# STM32L4R5 register map
File version: 2.4
CPU: CM4 r0p1, little endian, MPU, FPU, 4 interrupt priority bits
Registers are 32-bit, read-write, reset 0x0 unless marked. A register's access mark holds for its fields unless they carry their own. Offsets are from the block's base; [hi:lo] are bit positions; {n}, {i} and the like mark numbered series; 'fields as' and 'values as' point back to an identical list.

## RCC — Reset and clock control
Base 0x40021000
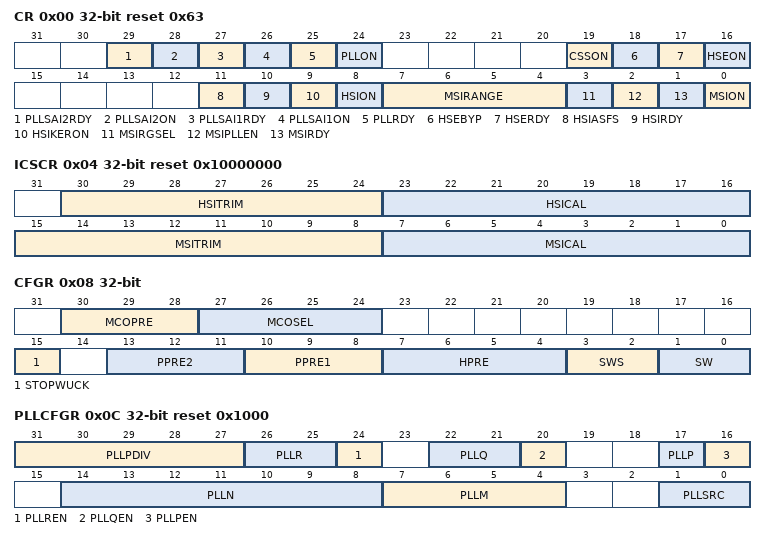
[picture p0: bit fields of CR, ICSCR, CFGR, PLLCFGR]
0x00 CR access per field reset 0x63 — Clock control register
  [29] PLLSAI2RDY ro — SAI2 PLL clock ready flag
  [28] PLLSAI2ON rw — SAI2 PLL enable
  [27] PLLSAI1RDY ro — SAI1 PLL clock ready flag
  [26] PLLSAI1ON rw — SAI1 PLL enable
  [25] PLLRDY ro — Main PLL clock ready flag
  [24] PLLON rw — Main PLL enable
  [19] CSSON wo — Clock security system enable
  [18] HSEBYP rw — HSE crystal oscillator bypass
  [17] HSERDY ro — HSE clock ready flag
  [16] HSEON rw — HSE clock enable
  [11] HSIASFS rw — HSI automatic start from Stop
  [10] HSIRDY ro — HSI clock ready flag
  [9] HSIKERON rw — HSI always enable for peripheral kernels
  [8] HSION rw — HSI clock enable
  [7:4] MSIRANGE rw — MSI clock ranges
    0=Range100K (range 0 around 100 kHz); 1=Range200K (range 1 around 200 kHz); 2=Range400K (range 2 around 400 kHz); 3=Range800K (range 3 around 800 kHz); 4=Range1M (range 4 around 1 MHz); 5=Range2M (range 5 around 2 MHz); 6=Range4M (range 6 around 4 MHz); 7=Range8M (range 7 around 8 MHz); 8=Range16M (range 8 around 16 MHz); 9=Range24M (range 9 around 24 MHz); 10=Range32M (range 10 around 32 MHz); 11=Range48M (range 11 around 48 MHz)
  [3] MSIRGSEL wo — MSI clock range selection
  [2] MSIPLLEN rw — MSI clock PLL enable
  [1] MSIRDY ro — MSI clock ready flag
  [0] MSION rw — MSI clock enable
0x04 ICSCR access per field reset 0x10000000 — Internal clock sources calibration register
  [30:24] HSITRIM rw — HSI clock trimming
  [23:16] HSICAL ro — HSI clock calibration
  [15:8] MSITRIM rw — MSI clock trimming
  [7:0] MSICAL ro — MSI clock calibration
0x08 CFGR access per field — Clock configuration register
  [30:28] MCOPRE ro — Microcontroller clock output prescaler
  [27:24] MCOSEL rw — Microcontroller clock output
  [15] STOPWUCK rw — Wakeup from Stop and CSS backup clock selection
  [13:11] PPRE2 rw — APB high-speed prescaler (APB2)
  [10:8] PPRE1 rw — PB low-speed prescaler (APB1)
  [7:4] HPRE rw — AHB prescaler
  [3:2] SWS ro — System clock switch status
  [1:0] SW rw — System clock switch
0x0C PLLCFGR reset 0x1000 — PLL configuration register
  [31:27] PLLPDIV — Main PLL division factor for PLLSAI2CLK
  [26:25] PLLR — Main PLL division factor for PLLCLK (system clock)
  [24] PLLREN — Main PLL PLLCLK output enable
  [22:21] PLLQ — Main PLL division factor for PLLUSB1CLK(48 MHz clock)
  [20] PLLQEN — Main PLL PLLUSB1CLK output enable
  [17] PLLP — Main PLL division factor for PLLSAI3CLK (SAI1 and SAI2 clock)
  [16] PLLPEN — Main PLL PLLSAI3CLK output enable
  [14:8] PLLN — Main PLL multiplication factor for VCO
  [7:4] PLLM — Division factor for the main PLL and audio PLL (PLLSAI1 and PLLSAI2) input clock
  [1:0] PLLSRC — Main PLL, PLLSAI1 and PLLSAI2 entry clock source
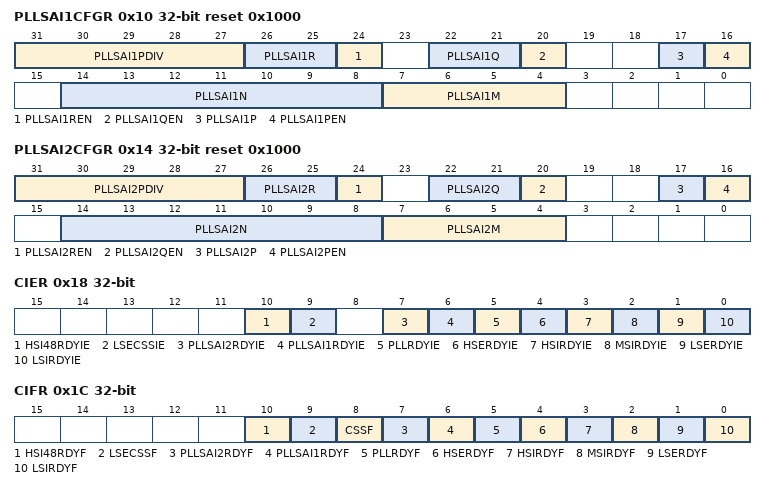
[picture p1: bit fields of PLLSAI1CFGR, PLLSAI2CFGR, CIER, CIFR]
0x10 PLLSAI1CFGR reset 0x1000 — PLLSAI1 configuration register
  [31:27] PLLSAI1PDIV — PLLSAI1 division factor for PLLSAI1CLK
  [26:25] PLLSAI1R — PLLSAI1 division factor for PLLADC1CLK (ADC clock)
  [24] PLLSAI1REN — PLLSAI1 PLLADC1CLK output enable
  [22:21] PLLSAI1Q — SAI1PLL division factor for PLLUSB2CLK (48 MHz clock)
  [20] PLLSAI1QEN — SAI1PLL PLLUSB2CLK output enable
  [17] PLLSAI1P — SAI1PLL division factor for PLLSAI1CLK (SAI1 or SAI2 clock)
  [16] PLLSAI1PEN — SAI1PLL PLLSAI1CLK output enable
  [14:8] PLLSAI1N — SAI1PLL multiplication factor for VCO
  [7:4] PLLSAI1M — Division factor for PLLSAI1 input clock
0x14 PLLSAI2CFGR reset 0x1000 — PLLSAI2 configuration register
  [31:27] PLLSAI2PDIV — PLLSAI2 division factor for PLLSAI2CLK
  [26:25] PLLSAI2R — PLLSAI2 division factor for PLLADC2CLK (ADC clock)
  [24] PLLSAI2REN — PLLSAI2 PLLADC2CLK output enable
  [22:21] PLLSAI2Q — SAI2PLL PLLSAI2CLK output enable
  [20] PLLSAI2QEN — PLLSAI2 division factor for PLLDISCLK
  [17] PLLSAI2P — SAI1PLL division factor for PLLSAI2CLK (SAI1 or SAI2 clock)
  [16] PLLSAI2PEN — SAI2PLL PLLSAI2CLK output enable
  [14:8] PLLSAI2N — SAI2PLL multiplication factor for VCO
  [7:4] PLLSAI2M — Division factor for PLLSAI2 input clock
0x18 CIER — Clock interrupt enable register
  [10] HSI48RDYIE — HSI48 ready interrupt enable
  [9] LSECSSIE — LSE clock security system interrupt enable
  [7] PLLSAI2RDYIE — PLLSAI2 ready interrupt enable
  [6] PLLSAI1RDYIE — PLLSAI1 ready interrupt enable
  [5] PLLRDYIE — PLL ready interrupt enable
  [4] HSERDYIE — HSE ready interrupt enable
  [3] HSIRDYIE — HSI ready interrupt enable
  [2] MSIRDYIE — MSI ready interrupt enable
  [1] LSERDYIE — LSE ready interrupt enable
  [0] LSIRDYIE — LSI ready interrupt enable
0x1C CIFR ro — Clock interrupt flag register
  [10] HSI48RDYF — HSI48 ready interrupt flag
  [9] LSECSSF — LSE Clock security system interrupt flag
  [8] CSSF — Clock security system interrupt flag
  [7] PLLSAI2RDYF — PLLSAI2 ready interrupt flag
  [6] PLLSAI1RDYF — PLLSAI1 ready interrupt flag
  [5] PLLRDYF — PLL ready interrupt flag
  [4] HSERDYF — HSE ready interrupt flag
  [3] HSIRDYF — HSI ready interrupt flag
  [2] MSIRDYF — MSI ready interrupt flag
  [1] LSERDYF — LSE ready interrupt flag
  [0] LSIRDYF — LSI ready interrupt flag
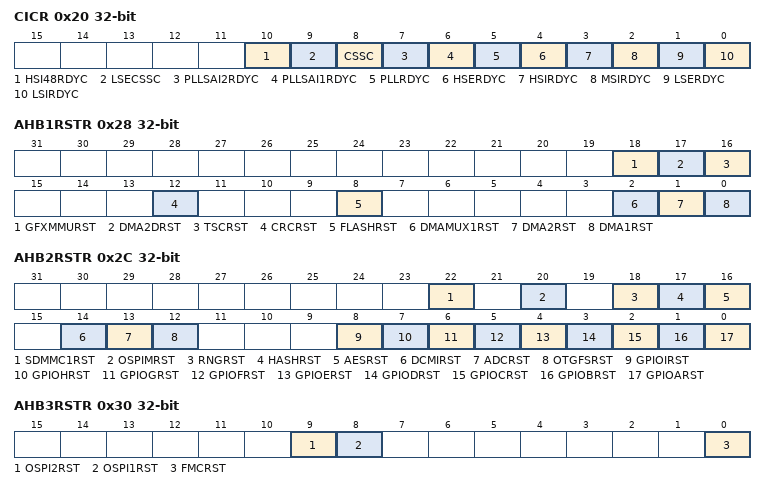
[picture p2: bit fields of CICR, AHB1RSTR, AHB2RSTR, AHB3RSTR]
0x20 CICR wo — Clock interrupt clear register
  [10] HSI48RDYC — HSI48 oscillator ready interrupt clear
  [9] LSECSSC — LSE Clock security system interrupt clear
  [8] CSSC — Clock security system interrupt clear
  [7] PLLSAI2RDYC — PLLSAI2 ready interrupt clear
  [6] PLLSAI1RDYC — PLLSAI1 ready interrupt clear
  [5] PLLRDYC — PLL ready interrupt clear
  [4] HSERDYC — HSE ready interrupt clear
  [3] HSIRDYC — HSI ready interrupt clear
  [2] MSIRDYC — MSI ready interrupt clear
  [1] LSERDYC — LSE ready interrupt clear
  [0] LSIRDYC — LSI ready interrupt clear
0x28 AHB1RSTR — AHB1 peripheral reset register
  [18] GFXMMURST — GFXMMU reset
  [17] DMA2DRST — DMA2D reset
  [16] TSCRST — Touch Sensing Controller reset
  [12] CRCRST — CRC reset
  [8] FLASHRST — Flash memory interface reset
  [2] DMAMUX1RST — DMAMUXRST
  [1] DMA2RST — DMA2 reset
  [0] DMA1RST — DMA1 reset
0x2C AHB2RSTR — AHB2 peripheral reset register
  [22] SDMMC1RST — SDMMC1 reset
  [20] OSPIMRST — OCTOSPI IO manager reset
  [18] RNGRST — Random number generator reset
  [17] HASHRST — Hash reset
  [16] AESRST — AES hardware accelerator reset
  [14] DCMIRST — Digital Camera Interface reset
  [13] ADCRST — ADC reset
  [12] OTGFSRST — USB OTG FS reset
  [8] GPIOIRST — IO port I reset
  [7] GPIOHRST — IO port H reset
  [6] GPIOGRST — IO port G reset
  [5] GPIOFRST — IO port F reset
  [4] GPIOERST — IO port E reset
  [3] GPIODRST — IO port D reset
  [2] GPIOCRST — IO port C reset
  [1] GPIOBRST — IO port B reset
  [0] GPIOARST — IO port A reset
0x30 AHB3RSTR — AHB3 peripheral reset register
  [9] OSPI2RST — OctOSPI2 memory interface reset
  [8] OSPI1RST — OSPI1 memory interface reset
  [0] FMCRST — Flexible memory controller reset
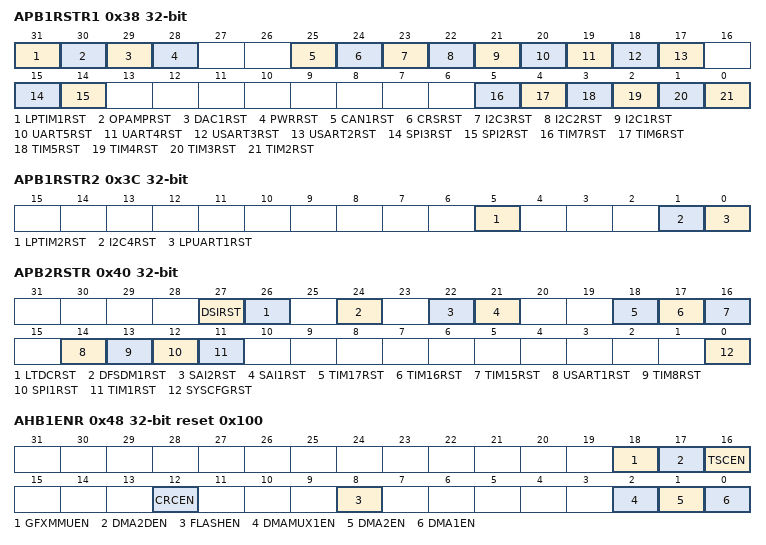
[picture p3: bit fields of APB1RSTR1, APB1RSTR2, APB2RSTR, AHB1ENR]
0x38 APB1RSTR1 — APB1 peripheral reset register 1
  [31] LPTIM1RST — Low Power Timer 1 reset
  [30] OPAMPRST — OPAMP interface reset
  [29] DAC1RST — DAC1 interface reset
  [28] PWRRST — Power interface reset
  [25] CAN1RST — CAN1 reset
  [24] CRSRST — CRS reset
  [23] I2C3RST — I2C3 reset
  [22] I2C2RST — I2C2 reset
  [21] I2C1RST — I2C1 reset
  [20] UART5RST — UART5 reset
  [19] UART4RST — UART4 reset
  [18] USART3RST — USART3 reset
  [17] USART2RST — USART2 reset
  [15] SPI3RST — SPI3 reset
  [14] SPI2RST — SPI2 reset
  [5] TIM7RST — TIM7 timer reset
  [4] TIM6RST — TIM6 timer reset
  [3] TIM5RST — TIM5 timer reset
  [2] TIM4RST — TIM3 timer reset
  [1] TIM3RST — TIM3 timer reset
  [0] TIM2RST — TIM2 timer reset
0x3C APB1RSTR2 — APB1 peripheral reset register 2
  [5] LPTIM2RST — Low-power timer 2 reset
  [1] I2C4RST — I2C4 reset
  [0] LPUART1RST — Low-power UART 1 reset
0x40 APB2RSTR — APB2 peripheral reset register
  [27] DSIRST — DSI reset
  [26] LTDCRST — LCD-TFT reset
  [24] DFSDM1RST — Digital filters for sigma-delata modulators (DFSDM) reset
  [22] SAI2RST — Serial audio interface 2 (SAI2) reset
  [21] SAI1RST — Serial audio interface 1 (SAI1) reset
  [18] TIM17RST — TIM17 timer reset
  [17] TIM16RST — TIM16 timer reset
  [16] TIM15RST — TIM15 timer reset
  [14] USART1RST — USART1 reset
  [13] TIM8RST — TIM8 timer reset
  [12] SPI1RST — SPI1 reset
  [11] TIM1RST — TIM1 timer reset
  [0] SYSCFGRST — System configuration (SYSCFG) reset
0x48 AHB1ENR reset 0x100 — AHB1 peripheral clock enable register
  [18] GFXMMUEN — Graphic MMU clock enable
  [17] DMA2DEN — DMA2D clock enable
  [16] TSCEN — Touch Sensing Controller clock enable
  [12] CRCEN — CRC clock enable
  [8] FLASHEN — Flash memory interface clock enable
  [2] DMAMUX1EN — DMAMUX clock enable
  [1] DMA2EN — DMA2 clock enable
  [0] DMA1EN — DMA1 clock enable
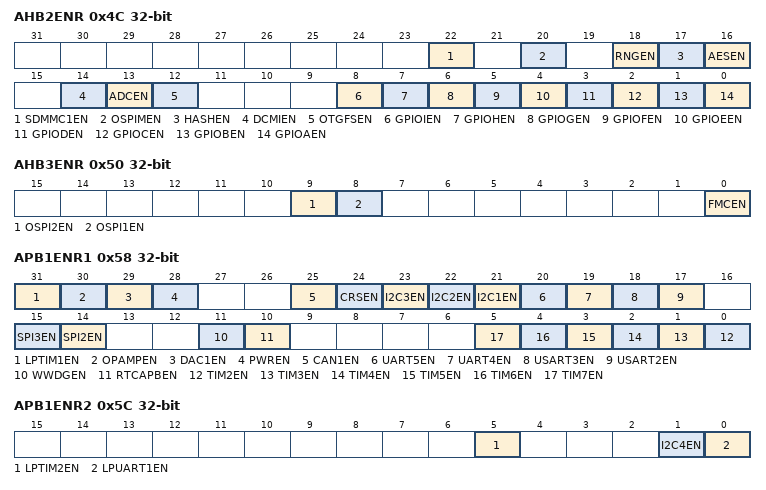
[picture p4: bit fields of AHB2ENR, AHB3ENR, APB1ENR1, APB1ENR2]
0x4C AHB2ENR — AHB2 peripheral clock enable register
  [22] SDMMC1EN — SDMMC1 clock enable
  [20] OSPIMEN — OctoSPI IO manager clock enable
  [18] RNGEN — Random Number Generator clock enable
  [17] HASHEN — HASH clock enable
  [16] AESEN — AES accelerator clock enable
  [14] DCMIEN — DCMI clock enable
  [13] ADCEN — ADC clock enable
    0=Disabled (ADC clock disabled); 1=Enabled (ADC clock enabled)
  [12] OTGFSEN — OTG full speed clock enable
  [8] GPIOIEN — IO port I clock enable
  [7] GPIOHEN — IO port H clock enable
  [6] GPIOGEN — IO port G clock enable
  [5] GPIOFEN — IO port F clock enable
  [4] GPIOEEN — IO port E clock enable
  [3] GPIODEN — IO port D clock enable
  [2] GPIOCEN — IO port C clock enable
  [1] GPIOBEN — IO port B clock enable
  [0] GPIOAEN — IO port A clock enable
0x50 AHB3ENR — AHB3 peripheral clock enable register
  [9] OSPI2EN — OSPI2EN memory interface clock enable
  [8] OSPI1EN — OSPI1 memory interface clock enable
  [0] FMCEN — Flexible memory controller clock enable
0x58 APB1ENR1
  [31] LPTIM1EN — Low power timer 1 clock enable
    0=Disabled (LPTIM1 clock disabled); 1=Enabled (LPTIM1 clock enabled)
  [30] OPAMPEN — OPAMP interface clock enable
  [29] DAC1EN — DAC1 interface clock enable
  [28] PWREN — Power interface clock enable
  [25] CAN1EN — CAN1 clock enable
  [24] CRSEN — Clock Recovery System clock enable
  [23] I2C3EN — I2C3 clock enable
    0=Disabled (I2C3 clock disabled); 1=Enabled (I2C3 clock enabled)
  [22] I2C2EN — I2C2 clock enable
    0=Disabled (I2C2 clock disabled); 1=Enabled (I2C2 clock enabled)
  [21] I2C1EN — I2C1 clock enable
    0=Disabled (I2C1 clock disabled); 1=Enabled (I2C1 clock enabled)
  [20] UART5EN — UART5 clock enable
  [19] UART4EN — UART4 clock enable
  [18] USART3EN — USART3 clock enable
  [17] USART2EN — USART2 clock enable
  [15] SPI3EN — SPI peripheral 3 clock enable
  [14] SPI2EN — SPI2 clock enable
  [11] WWDGEN — Window watchdog clock enable
  [10] RTCAPBEN — RTC APB clock enable
  [n-2] TIM{n}EN (n=2..7) — TIM{n} timer clock enable
0x5C APB1ENR2 — APB1 peripheral clock enable register 2
  [5] LPTIM2EN
    0=Disabled (LPTIM2 clock disabled); 1=Enabled (LPTIM2 clock enabled)
  [1] I2C4EN — I2C4 clock enable
  [0] LPUART1EN — Low power UART 1 clock enable
    0=Disabled (LPUART1 clock disabled); 1=Enabled (LPUART1 clock enabled)
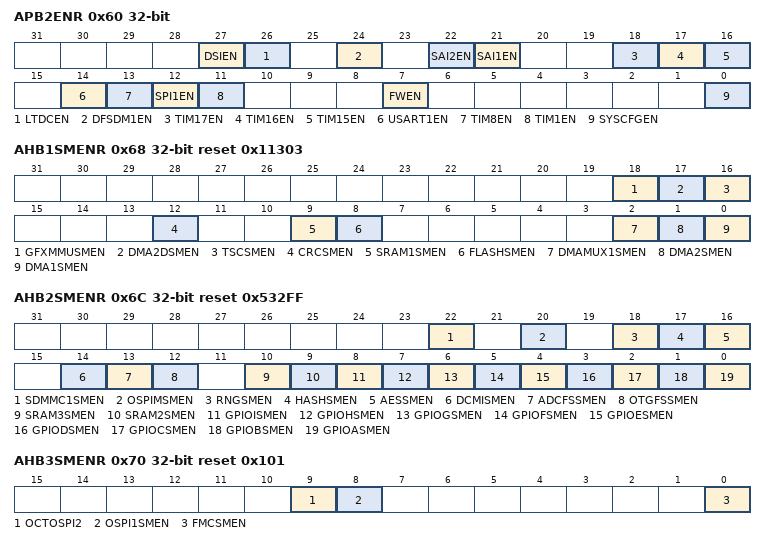
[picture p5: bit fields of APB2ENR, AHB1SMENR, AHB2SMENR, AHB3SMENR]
0x60 APB2ENR
  [27] DSIEN — DSI clock enable
  [26] LTDCEN — LCD-TFT clock enable
  [24] DFSDM1EN — DFSDM timer clock enable
  [22] SAI2EN — SAI2 clock enable
  [21] SAI1EN — SAI1 clock enable
  [18] TIM17EN — TIM17 timer clock enable
  [17] TIM16EN — TIM16 timer clock enable
  [16] TIM15EN — TIM15 timer clock enable
  [14] USART1EN — USART1clock enable
    0=Disabled (USART1 clock disabled); 1=Enabled (USART1 clock enabled)
  [13] TIM8EN — TIM8 timer clock enable
  [12] SPI1EN — SPI1 clock enable
  [11] TIM1EN — TIM1 timer clock enable
  [7] FWEN — Firewall clock enable
  [0] SYSCFGEN — SYSCFG clock enable
0x68 AHB1SMENR reset 0x11303 — AHB1 peripheral clocks enable in Sleep and Stop modes register
  [18] GFXMMUSMEN — GFXMMU clock enable during Sleep and Stop modes
  [17] DMA2DSMEN — DMA2D clock enable during Sleep and Stop modes
  [16] TSCSMEN — Touch Sensing Controller clocks enable during Sleep and Stop modes
  [12] CRCSMEN
  [9] SRAM1SMEN — SRAM1 interface clocks enable during Sleep and Stop modes
  [8] FLASHSMEN — Flash memory interface clocks enable during Sleep and Stop modes
  [2] DMAMUX1SMEN — DMAMUX clock enable during Sleep and Stop modes
  [1] DMA2SMEN — DMA2 clocks enable during Sleep and Stop modes
  [0] DMA1SMEN — DMA1 clocks enable during Sleep and Stop modes
0x6C AHB2SMENR reset 0x532FF — AHB2 peripheral clocks enable in Sleep and Stop modes register
  [22] SDMMC1SMEN — SDMMC1 clocks enable during Sleep and Stop modes
  [20] OSPIMSMEN — OctoSPI IO manager clocks enable during Sleep and Stop modes
  [18] RNGSMEN — Random Number Generator clocks enable during Sleep and Stop modes
  [17] HASHSMEN — HASH clock enable during Sleep and Stop modes
  [16] AESSMEN — AES accelerator clocks enable during Sleep and Stop modes
  [14] DCMISMEN — DCMI clock enable during Sleep and Stop modes
  [13] ADCFSSMEN — ADC clocks enable during Sleep and Stop modes
  [12] OTGFSSMEN — OTG full speed clocks enable during Sleep and Stop modes
  [10] SRAM3SMEN — SRAM2 interface clocks enable during Sleep and Stop modes
  [9] SRAM2SMEN — SRAM2 interface clocks enable during Sleep and Stop modes
  [8] GPIOISMEN — IO port I clocks enable during Sleep and Stop modes
  [7] GPIOHSMEN — IO port H clocks enable during Sleep and Stop modes
  [6] GPIOGSMEN — IO port G clocks enable during Sleep and Stop modes
  [5] GPIOFSMEN — IO port F clocks enable during Sleep and Stop modes
  [4] GPIOESMEN — IO port E clocks enable during Sleep and Stop modes
  [3] GPIODSMEN — IO port D clocks enable during Sleep and Stop modes
  [2] GPIOCSMEN — IO port C clocks enable during Sleep and Stop modes
  [1] GPIOBSMEN — IO port B clocks enable during Sleep and Stop modes
  [0] GPIOASMEN — IO port A clocks enable during Sleep and Stop modes
0x70 AHB3SMENR reset 0x101 — AHB3 peripheral clocks enable in Sleep and Stop modes register
  [9] OCTOSPI2 — OctoSPI2 memory interface clocks enable during Sleep and Stop modes
  [8] OSPI1SMEN — OSPI1 memory interface clock enable during Sleep and Stop modes
  [0] FMCSMEN — Flexible memory controller clocks enable during Sleep and Stop modes
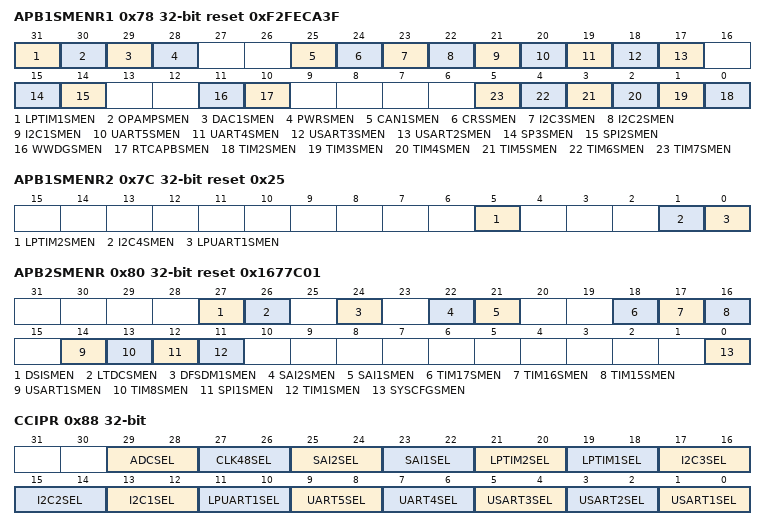
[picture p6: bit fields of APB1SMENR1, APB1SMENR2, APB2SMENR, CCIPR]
0x78 APB1SMENR1 reset 0xF2FECA3F
  [31] LPTIM1SMEN — Low power timer 1 clocks enable during Sleep and Stop modes
  [30] OPAMPSMEN — OPAMP interface clocks enable during Sleep and Stop modes
  [29] DAC1SMEN — DAC1 interface clocks enable during Sleep and Stop modes
  [28] PWRSMEN — Power interface clocks enable during Sleep and Stop modes
  [25] CAN1SMEN — CAN1 clocks enable during Sleep and Stop modes
  [24] CRSSMEN — CRS clock enable during Sleep and Stop modes
  [23] I2C3SMEN — I2C3 clocks enable during Sleep and Stop modes
  [22] I2C2SMEN — I2C2 clocks enable during Sleep and Stop modes
  [21] I2C1SMEN — I2C1 clocks enable during Sleep and Stop modes
  [20] UART5SMEN — UART5 clocks enable during Sleep and Stop modes
  [19] UART4SMEN — UART4 clocks enable during Sleep and Stop modes
  [18] USART3SMEN — USART3 clocks enable during Sleep and Stop modes
  [17] USART2SMEN — USART2 clocks enable during Sleep and Stop modes
  [15] SP3SMEN — SPI3 clocks enable during Sleep and Stop modes
  [14] SPI2SMEN — SPI2 clocks enable during Sleep and Stop modes
  [11] WWDGSMEN — Window watchdog clocks enable during Sleep and Stop modes
  [10] RTCAPBSMEN — RTC APB clock enable during Sleep and Stop modes
  [n-2] TIM{n}SMEN (n=2..7) — TIM{n} timer clocks enable during Sleep and Stop modes
0x7C APB1SMENR2 reset 0x25 — APB1 peripheral clocks enable in Sleep and Stop modes register 2
  [5] LPTIM2SMEN
  [1] I2C4SMEN — I2C4 clocks enable during Sleep and Stop modes
  [0] LPUART1SMEN — Low power UART 1 clocks enable during Sleep and Stop modes
0x80 APB2SMENR reset 0x1677C01
  [27] DSISMEN — DSI clocks enable during Sleep and Stop modes
  [26] LTDCSMEN — LCD-TFT timer clocks enable during Sleep and Stop modes
  [24] DFSDM1SMEN — DFSDM timer clocks enable during Sleep and Stop modes
  [22] SAI2SMEN — SAI2 clocks enable during Sleep and Stop modes
  [21] SAI1SMEN — SAI1 clocks enable during Sleep and Stop modes
  [18] TIM17SMEN — TIM17 timer clocks enable during Sleep and Stop modes
  [17] TIM16SMEN — TIM16 timer clocks enable during Sleep and Stop modes
  [16] TIM15SMEN — TIM15 timer clocks enable during Sleep and Stop modes
  [14] USART1SMEN — USART1clocks enable during Sleep and Stop modes
  [13] TIM8SMEN — TIM8 timer clocks enable during Sleep and Stop modes
  [12] SPI1SMEN — SPI1 clocks enable during Sleep and Stop modes
  [11] TIM1SMEN — TIM1 timer clocks enable during Sleep and Stop modes
  [0] SYSCFGSMEN — SYSCFG clocks enable during Sleep and Stop modes
0x88 CCIPR
  [29:28] ADCSEL — ADCs clock source selection
    0=No clock selected; 1=PLLSAI1 (PLLSAI1 clock selected); 2=PLLSAI2 (PLLSAI2 clock selected (only for STM32L47x/L48x/L49x/L4Ax devices)); 3=SYSCLK (SYSCLK clock selected)
  [27:26] CLK48SEL — 48 MHz clock source selection
    0=HSI48 (HSI48 clock selected (only for STM32L41x/L42x/L43x/L44x/L45x/L46x/L49x/L4Ax devices, otherwise no clock selected)); 1=PLLSAI1 (PLLSAI1 clock selected); 2=PLL (PLL clock selected); 3=MSI (MSI clock selected)
  [25:24] SAI2SEL — SAI2 clock source selection
  [23:22] SAI1SEL — SAI1 clock source selection
  [21:20] LPTIM2SEL — Low power timer 2 clock source selection
    0=PCLK (PCLK clock selected); 1=LSI (LSI clock selected); 2=HSI16 (HSI16 clock selected); 3=LSE (LSE clock selected)
  [19:18] LPTIM1SEL — Low power timer 1 clock source selection
    values as LPTIM2SEL
  [17:16] I2C3SEL — I2C3 clock source selection
    0=PCLK (PCLK clock selected); 1=SYSCLK (SYSCLK clock selected); 2=HSI16 (HSI16 clock selected)
  [15:14] I2C2SEL — I2C2 clock source selection
    values as I2C3SEL
  [13:12] I2C1SEL — I2C1 clock source selection
    values as I2C3SEL
  [11:10] LPUART1SEL — LPUART1 clock source selection
    0=PCLK (PCLK clock selected); 1=SYSCLK (SYSCLK clock selected); 2=HSI16 (HSI16 clock selected); 3=LSE (LSE clock selected)
  [9:8] UART5SEL — UART5 clock source selection
  [7:6] UART4SEL — UART4 clock source selection
  [5:4] USART3SEL — USART3 clock source selection
    values as LPUART1SEL
  [3:2] USART2SEL — USART2 clock source selection
    values as LPUART1SEL
  [1:0] USART1SEL — USART1 clock source selection
    values as LPUART1SEL
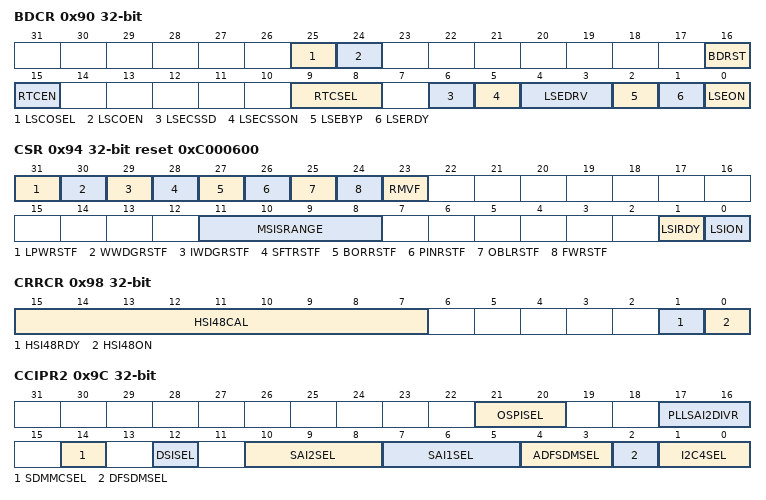
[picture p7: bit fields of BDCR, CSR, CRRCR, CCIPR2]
0x90 BDCR access per field
  [25] LSCOSEL rw — Low speed clock output selection
  [24] LSCOEN rw — Low speed clock output enable
  [16] BDRST rw — Backup domain software reset
  [15] RTCEN rw — RTC clock enable
    0=Disabled (RTC clock disabled); 1=Enabled (RTC clock enabled)
  [9:8] RTCSEL rw — RTC clock source selection
    0=NoClock; 1=LSE (LSE oscillator clock selected); 2=LSI (LSI oscillator clock selected); 3=HSE (HSE oscillator clock divided by 32 selected)
  [6] LSECSSD ro
  [5] LSECSSON rw
  [4:3] LSEDRV rw — SE oscillator drive capability
  [2] LSEBYP rw — LSE oscillator bypass
  [1] LSERDY ro — LSE oscillator ready
  [0] LSEON rw — LSE oscillator enable
0x94 CSR access per field reset 0xC000600
  [31] LPWRSTF ro — Low-power reset flag
  [30] WWDGRSTF ro — Window watchdog reset flag
  [29] IWDGRSTF ro — Independent window watchdog reset flag
  [28] SFTRSTF ro — Software reset flag
  [27] BORRSTF ro — BOR flag
  [26] PINRSTF ro — Pin reset flag
  [25] OBLRSTF ro — Option byte loader reset flag
  [24] FWRSTF ro — Firewall reset flag
  [23] RMVF rw — Remove reset flag
  [11:8] MSISRANGE rw — SI range after Standby mode
  [1] LSIRDY ro — LSI oscillator ready
  [0] LSION rw — LSI oscillator enable
0x98 CRRCR access per field — Clock recovery RC register
  [15:7] HSI48CAL ro — HSI48 clock calibration
  [1] HSI48RDY ro — HSI48 clock ready flag
  [0] HSI48ON rw — HSI48 clock enable
0x9C CCIPR2 — Peripherals independent clock configuration register
  [21:20] OSPISEL — Octospi clock source selection
  [17:16] PLLSAI2DIVR — division factor for LTDC clock
  [14] SDMMCSEL — SDMMC clock selection
  [12] DSISEL — clock selection
  [10:8] SAI2SEL — SAI2 clock source selection
  [7:5] SAI1SEL — SAI1 clock source selection
  [4:3] ADFSDMSEL — Digital filter for sigma delta modulator audio clock source selection
  [2] DFSDMSEL — Digital filter for sigma delta modulator kernel clock source selection
  [1:0] I2C4SEL — I2C4 clock source selection
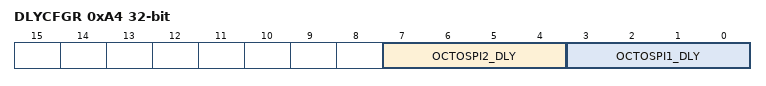
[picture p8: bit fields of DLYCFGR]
0xA4 DLYCFGR — Delay configuration register
  [7:4] OCTOSPI2_DLY — Delay sampling configuration on OCTOSPI2
  [3:0] OCTOSPI1_DLY — Delay sampling configuration on OCTOSPI1
